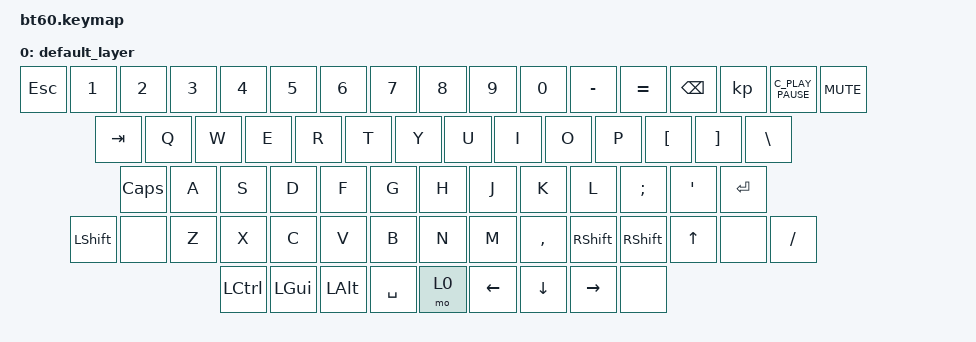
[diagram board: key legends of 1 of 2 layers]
#include <behaviors.dtsi>
#include <dt-bindings/zmk/backlight.h>
#include <dt-bindings/zmk/bt.h>
#include <dt-bindings/zmk/keys.h>
#include <dt-bindings/zmk/rgb.h>

/ {
    keymap {
        compatible = "zmk,keymap";

        default_layer {
            // ------------------------------------------------------------------------------------------
            // | ESC |  1  |  2  |  3  |  4  |  5  |  6  |  7  |  8  |  9  |  0  |  -  |  = |BKSP|C_MUTE |
            // | TAB   |  Q  |  W  |  E  |  R  |  T  |  Y  |  U  |  I  |  O  |  P  |  [  |  ]  |    \    |
            // | CAPS   |  A  |  S  |  D  |  F  |  G  |  H  |  J  |  K  |  L  |  ;  |  '  |     ENTER    |
            // | SHFT  |NONE|  Z  |  X  |  C  |  V  |  B  |  N  |  M  |  ,  | . |/| SHFT | UP |       |/ |
            // |  CTL  |  WIN  |  ALT  |           SPACE              | M0  |      LEFT | DOWN | RIGHT|  |
            // ------------------------------------------------------------------------------------------

            bindings = <
       &kp ESC     &kp N1    &kp N2    &kp N3     &kp N4  &kp N5    &kp N6    &kp N7     &kp N8     &kp N9           &kp N0         &kp MINUS          &kp EQUAL  &kp BSPC kp C_PLAY_PAUSE  &kp C_MUTE
       &kp TAB      &kp Q     &kp W     &kp E      &kp R   &kp T     &kp Y     &kp U      &kp I      &kp O            &kp P  &kp LEFT_BRACKET  &kp RIGHT_BRACKET                  &kp BSLH
      &kp CAPS      &kp A     &kp S     &kp D      &kp F   &kp G     &kp H     &kp J      &kp K      &kp L    &kp SEMICOLON           &kp SQT          &kp ENTER
&kp LEFT_SHIFT      &none     &kp Z     &kp X      &kp C   &kp V     &kp B     &kp N      &kp M  &kp COMMA  &kp RIGHT_SHIFT         &kp RSHFT             &kp UP                     &none    &kp FSLH
                &kp LCTRL  &kp LGUI  &kp LALT  &kp SPACE   &mo 0  &kp LEFT  &kp DOWN  &kp RIGHT      &none
            >;

            sensor-bindings = <&inc_dec_kp C_VOL_UP C_VOL_DN>;
        };

        raise {
            // ------------------------------------------------------------------------------------------
            // |GRAVE| F1  | F2  | F3  | F4  | F5  | F6  | F7  | F8  | F9  | F10 | F11 | F12 |BKSP | DEL |
            // | TAB  |  Q  |  W  |  E  | HUI | HUD |  Y  |  U  | INS |  O  |PSCRN| SLCK| P_B | RGB_TOG  |
            // | CAPS  |  A  |  S  |  D  | BRI | BRD |  H  |  J  |  K  |  L  | HOME| PGUP|      BOOT     |
            // | SHFT |NONE|VOLDN|VOLUP|MUTE|BLINC|BLDEC|  N  |  M  |  ,  | END | PGDN | SHFT|BL_TOG| 1  |
            // | BT_PRV| BT_NXT|  ALT  |           SPACE              | RALT| CTRL | LEFT |RESET| BT_CLR |
            // ------------------------------------------------------------------------------------------

            bindings = <
&kp GRAVE      &kp F1        &kp F2        &kp F3           &kp F4           &kp F5      &kp F6  &kp F7      &kp F8      &kp F9    &kp F10    &kp F11          &kp F12           &trans  &trans
   &trans      &trans        &trans        &trans  &rgb_ug RGB_HUI  &rgb_ug RGB_HUD      &trans  &trans     &kp INS      &trans  &kp PSCRN   &kp SLCK  &kp PAUSE_BREAK  &rgb_ug RGB_TOG
   &trans      &trans        &trans        &trans  &rgb_ug RGB_BRI  &rgb_ug RGB_BRD      &trans  &trans      &trans      &trans   &kp HOME  &kp PG_UP      &bootloader
   &trans       &none  &kp C_VOL_DN  &kp C_VOL_UP       &kp C_MUTE       &bl BL_INC  &bl BL_DEC  &trans      &trans      &trans    &kp END  &kp PG_DN           &trans       &bl BL_TOG  &trans
           &bt BT_PRV    &bt BT_NXT        &trans           &trans           &trans      &trans  &trans  &sys_reset  &bt BT_CLR
            >;

            sensor-bindings = <&inc_dec_kp C_VOL_UP C_VOL_DN>;
        };
    };
};
